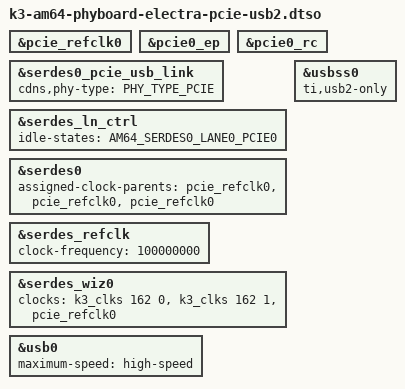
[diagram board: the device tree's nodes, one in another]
// SPDX-License-Identifier: GPL-2.0
/*
 * DT overlay for PCIe support (limits USB to 2.0/high-speed)
 *
 * Copyright (C) 2021 PHYTEC America, LLC - https://www.phytec.com
 * Author: Matt McKee <mmckee@phytec.com>
 */

/dts-v1/;
/plugin/;

#include <dt-bindings/mux/ti-serdes.h>
#include <dt-bindings/phy/phy.h>
#include <dt-bindings/phy/phy-cadence.h>

&pcie_refclk0 {
	status = "okay";
};

&pcie0_ep {
	status = "okay";
};

&pcie0_rc {
	status = "okay";
};

&serdes0_pcie_usb_link {
	cdns,phy-type = <PHY_TYPE_PCIE>;
};

&serdes_ln_ctrl {
	idle-states = <AM64_SERDES0_LANE0_PCIE0>;
};

&serdes0 {
	assigned-clock-parents = <&pcie_refclk0>, <&pcie_refclk0>, <&pcie_refclk0>;
};

&serdes_refclk {
	clock-frequency = <100000000>;
};

/*
 * Assign pcie_refclk0 to serdes_wiz0 as ext_ref_clk.
 * This makes sure that the clock generator gets enabled at the right time.
 */
&serdes_wiz0 {
	clocks = <&k3_clks 162 0>, <&k3_clks 162 1>, <&pcie_refclk0>;
};

&usbss0 {
	ti,usb2-only;
};

&usb0 {
	maximum-speed = "high-speed";
};
